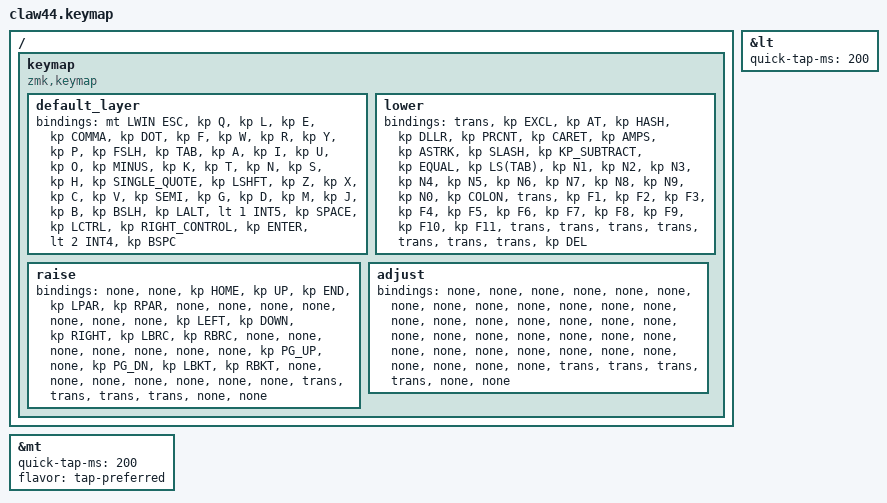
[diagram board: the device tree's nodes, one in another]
/*
 * Copyright (c) 2021 The ZMK Contributors
 *
 * SPDX-License-Identifier: MIT
 */

#include <behaviors.dtsi>
#include <dt-bindings/zmk/keys.h>

#define LOWR 1
#define RAIS 2
#define ADJT 3

/* the following lines are for using Claw44 on JIS layout */
//#define JP_UND   LS(INT1)  // _
//#define JP_COL   SQT       // :
//#define JP_SQT   LS(N7)    // '
//#define JP_DQT   LS(N2)    // "
//#define JP_MUHN  INT5      // mukenkan
//#define JP_HENK  INT4      // hankan
//#define JP_AT    LBKT      // @
//#define JP_CARET EQUAL     // ^
//#define JP_AMPS  LS(N6)    // &
//#define JP_LPAR  LS(N8)    // (
//#define JP_RPAR  LPAR      // )
//#define JP_TILDE LS(EQUAL) // ~
//#define JP_LBLK  RBKT      // [
//#define JP_RBLK  NUHS      // ]
//#define JP_PIPE  LS(INT3)  // |
//#define JP_ASTR  LS(SQT)   // ASTER
//#define JP_LBKT  LS(RBKT)  // {
//#define JP_RBKT  LS(NUHS)  // }
//#define JP_GRV   LS(LBKT)  // `
//#define JP_EQL   LS(MINUS) // =
//#define JP_PLUS  LS(SEMI)  // +
//#define JP_YEN   INT1      // yen
/* the following lines are for shortening keymap section */
//#define MACRO_1_2 &macro_1_2 &kp &kp
//#define A_DWN    &mt LALT DOWN
//#define S_MUHN   &mt LSHFT JP_MUHN
//#define L_SPC    &lt LOWR SPACE
//#define C_BS     &mt LCTRL BSPC
//#define C_DEL    &mt RCTRL DEL
//#define R_ENT    &lt RAIS ENTER
//#define S_HENK   &mt RSHFT JP_HENK
//#define A_UP     &mt RALT UP

&lt { quick-tap-ms = <200>; };

&mt {
    quick-tap-ms = <200>;
    flavor = "tap-preferred";
};

/ {
    //    macros {
    //        ZMK_MACRO(macro_1,
    //            wait-ms = <30>;
    //            tap-ms = <40>;
    //            bindings
    //                = <&kp LC(LA(DEL))>
    //                , <&macro_wait_time 1500>
    //                , <&kp DEL>
    //                , <&macro_wait_time 30>
    //                , <&kp A &kp B &kp C &kp ENTER>
    //                ;
    //        )
    //
    //        ZMK_MACRO(macro_2,
    //            wait-ms = <30>;
    //            tap-ms = <40>;
    //            bindings
    //                = <&kp N1 &kp N2 &kp N3>
    //                , <&macro_wait_time 300>
    //                , <&kp TAB>
    //                , <&macro_wait_time 30>
    //                , <&kp A &kp B &kp C>
    //                , <&macro_wait_time 300>
    //                , <&kp TAB>
    //                , <&macro_wait_time 30>
    //                , <&kp ENTER>
    //                ;
    //        )
    //
    //        ZMK_MACRO(macro_3,
    //            wait-ms = <300>;
    //            tap-ms = <40>;
    //            bindings
    //                = <&kp LS(TAB)>
    //                , <&macro_wait_time 1000>
    //                , <&kp HOME>
    //                , <&macro_wait_time 300>
    //                , <&kp TAB &kp END>    
    //                ;
    //        )
    //    };
    //
    //    behaviors {
    //        macro_1_2: macro_1_2 {
    //            compatible = "zmk,behavior-hold-tap";
    //            bindings = <&macro_2>, <&macro_1>;
    //            #binding-cells = <2>;
    //            tapping-term-ms = <300>;
    //        };
    //    };

    keymap {
        compatible = "zmk,keymap";

        default_layer {
            /* -------------------------------------------------------------   -------------------------------------------------------------
   |   ESC   |    Q    |    W    |    E    |    R    |    T    |   |    Y    |    U    |    I    |    O    |    P    |   -  _  |
   |   TAB   |    A    |    S    |    D    |    F    |    G    |   |    H    |    J    |    K    |    L    |   ;  :  |   '  "  |
   |LEFT  GUI|    Z    |    X    |    C    |    V    |    B    |   |    N    |    M    |   ,  <  |   .  >  |   /  ?  |  RIGHT  |
   --------------------|DOWN ALT |MUHEN SFT|SPC lower|BSPC CTL |   | DEL CTL |ENT raise|HENK SFT |  UP SFT |--------------------
                       -----------------------------------------   -----------------------------------------
*/

            bindings = <
&mt LWIN ESC  &kp Q  &kp L  &kp E  &kp COMMA  &kp DOT  &kp F  &kp W  &kp R  &kp Y  &kp P  &kp FSLH  &kp TAB  &kp A  &kp I  &kp U  &kp O  &kp MINUS  &kp K  &kp T  &kp N  &kp S  &kp H  &kp SINGLE_QUOTE  &kp LSHFT  &kp Z  &kp X  &kp C  &kp V  &kp SEMI  &kp G  &kp D  &kp M  &kp J  &kp B  &kp BSLH  &kp LALT  &lt 1 INT5  &kp SPACE  &kp LCTRL  &kp RIGHT_CONTROL  &kp ENTER  &lt 2 INT4  &kp BSPC
            >;
        };

        lower {
            /* -------------------------------------------------------------   -------------------------------------------------------------
   |MACRO_1_2|         |         |    F8   |  Ctrl+Y |         |   | MACRO_3 |         |         |         |  PSCRN  |   INS   |
   |   CAPS  |    !    |    @    |    #    |    $    |    %    |   |   LEFT  |   DOWN  |    UP   |  RIGHT  |    {    |    }    |
   |         |    ^    |    &    |    (    |    )    |    ~    |   |   HOME  |  PG_DN  |  PG_UP  |   END   |    |    |   APP   |
   --------------------|  ENTER  |   DEL   |         |BSPC CTL |   | DEL CTL |  adjust |HENK SFT |  UP SFT |--------------------
                        -----------------------------------------   -----------------------------------------
*/

            bindings = <
&trans  &kp EXCL  &kp AT  &kp HASH  &kp DLLR  &kp PRCNT  &kp CARET  &kp AMPS  &kp ASTRK  &kp SLASH  &kp KP_SUBTRACT  &kp EQUAL  &kp LS(TAB)  &kp N1  &kp N2  &kp N3  &kp N4  &kp N5  &kp N6  &kp N7  &kp N8  &kp N9  &kp N0  &kp COLON  &trans  &kp F1  &kp F2  &kp F3  &kp F4  &kp F5  &kp F6  &kp F7  &kp F8  &kp F9  &kp F10  &kp F11  &trans  &trans  &trans  &trans  &trans  &trans  &trans  &kp DEL
            >;
        };

        raise {
            /* -------------------------------------------------------------   -------------------------------------------------------------
   |    F1   |    F2   |    F3   |    F4   |    F5   |    F6   |   |    `    |    =    |    +    |  ASTER  |    /    |    -    |
   |         |    1    |    2    |    3    |    4    |    5    |   |    6    |    7    |    8    |    9    |    0    |    \    |
   |  F7 GUI |    F8   |    F9   |   F10   |   F11   |   F12   |   |    [    |    ]    |    ,    |    .    |         |         |
   --------------------|         |         |  adjust |BSPC CTL |   | DEL CTL |         |         |         |--------------------
                       -----------------------------------------   -----------------------------------------
*/

            bindings = <
&none  &none  &kp HOME  &kp UP  &kp END  &kp LPAR  &kp RPAR  &none  &none  &none  &none  &none  &none  &none  &kp LEFT  &kp DOWN  &kp RIGHT  &kp LBRC  &kp RBRC  &none  &none  &none  &none  &none  &none  &none  &kp PG_UP  &none  &kp PG_DN  &kp LBKT  &kp RBKT  &none  &none  &none  &none  &none  &none  &none  &trans  &trans  &trans  &trans  &none  &none
            >;
        };

        adjust {
            /* -------------------------------------------------------------   -------------------------------------------------------------
   |         |         |         |         |         |         |   |         |    7    |    8    |    9    |         |         |
   |  BT_CLR |         |         |         |         |         |   |         |    4    |    5    |    6    |         |         |
   |  BT_NXT |         |         |         |         |         |   |    0    |    1    |    2    |    3    |         |         |
   --------------------|         |         |         |BSPC CTL |   | DEL CTL |    ,    |    .    |         |--------------------
                       -----------------------------------------   -----------------------------------------
*/

            bindings = <
&none  &none  &none  &none  &none  &none  &none  &none  &none  &none  &none  &none  &none  &none  &none  &none  &none  &none  &none  &none  &none  &none  &none  &none  &none  &none  &none  &none  &none  &none  &none  &none  &none  &none  &none  &none  &none  &none  &trans  &trans  &trans  &trans  &none  &none
            >;
        };
    };
};
